# CY8C5868AXI_LP035 register map
File version: 0.1
Registers are 8-bit, read-write, no defined reset value unless marked. A register's access mark holds for its fields unless they carry their own. Offsets are from the block's base; [hi:lo] are bit positions.

## I2C_1
Base 0x00000000
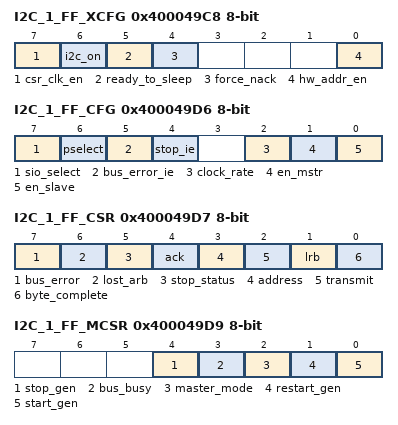
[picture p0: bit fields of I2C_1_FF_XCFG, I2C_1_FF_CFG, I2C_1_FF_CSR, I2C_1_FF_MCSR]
0x400049C8 I2C_1_FF_XCFG — Extended Configuration Register: I2C_XCFG
  [7] csr_clk_en, [6] i2c_on, [5] ready_to_sleep ro, [4] force_nack, [0] hw_addr_en
0x400049CA I2C_1_FF_ADDR — Slave Adddress Register: I2C_ADR
  [6:0] slave_address — This register holds the slave's 7-bit address.
0x400049D6 I2C_1_FF_CFG — Configuration Register: I2C_CFG
  [7] sio_select, [6] pselect, [5] bus_error_ie, [4] stop_ie, [2] clock_rate, [1] en_mstr, [0] en_slave
0x400049D7 I2C_1_FF_CSR — Control and Status Register: I2C_CSR
  [7] bus_error, [6] lost_arb, [5] stop_status, [4] ack, [3] address, [2] transmit, [1] lrb, [0] byte_complete
0x400049D8 I2C_1_FF_DATA — Data Register: I2C_D
  [7:0] data — This register provides read/write access to the Shift register.
0x400049D9 I2C_1_FF_MCSR — Master Control and Status Register: I2C_MCSR
  [4] stop_gen, [3] bus_busy ro, [2] master_mode ro, [1] restart_gen, [0] start_gen
0x400049DB I2C_1_FF__CLK_DIV1 — Divider of BUS_CLK low part: I2C_CLK_DIV1
  [7:0] Div
0x400049DC I2C_1_FF__CLK_DIV2 — Divider high part: I2C_CLK_DIV1
  [1:0] Div
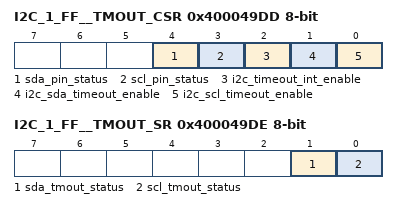
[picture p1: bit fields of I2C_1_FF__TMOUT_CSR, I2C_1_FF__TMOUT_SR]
0x400049DD I2C_1_FF__TMOUT_CSR — Extended Configuration Register: I2C_TMOUT_CSR
  [4] sda_pin_status, [3] scl_pin_status, [2] i2c_timeout_int_enable ro, [1] i2c_sda_timeout_enable, [0] i2c_scl_timeout_enable
0x400049DE I2C_1_FF__TMOUT_SR — Extended Configuration Register: I2C_TMOUT_SR
  [1] sda_tmout_status, [0] scl_tmout_status
0x400049DF I2C_1_FF__TMOUT_CFG0 — Extended Configuration Register: TMOUT_CFG0
  [7:0] timeout_period_lowbyte
0x400049E0 I2C_1_FF__TMOUT_CFG1 — Extended Configuration Register: TMOUT_CFG1
  [3:0] timeout_period_highnibble

## PC — UART
Base 0x00000000
0x4000642F RX_PC_RX_ADDRESS1 — RX Address1 Register
0x4000643F RX_PC_RX_ADDRESS2 — RX Address2 Register
0x4000644F RX_PC_RX_DATA — RX Data Register
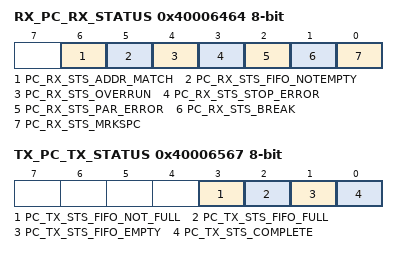
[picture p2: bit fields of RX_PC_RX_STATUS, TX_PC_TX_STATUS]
0x40006464 RX_PC_RX_STATUS — RX status register
  [6] PC_RX_STS_ADDR_MATCH ro, [5] PC_RX_STS_FIFO_NOTEMPTY ro, [4] PC_RX_STS_OVERRUN ro, [3] PC_RX_STS_STOP_ERROR ro, [2] PC_RX_STS_PAR_ERROR ro, [1] PC_RX_STS_BREAK ro, [0] PC_RX_STS_MRKSPC ro
0x40006547 TX_PC_TX_DATA — TX Data Register
0x40006567 TX_PC_TX_STATUS — TX status register
  [3] PC_TX_STS_FIFO_NOT_FULL ro, [2] PC_TX_STS_FIFO_FULL ro, [1] PC_TX_STS_FIFO_EMPTY ro, [0] PC_TX_STS_COMPLETE ro

## Surtidor — UART
Base 0x00000000
0x4000642E RX_Surtidor_RX_ADDRESS1 — RX Address1 Register
0x4000643E RX_Surtidor_RX_ADDRESS2 — RX Address2 Register
0x40006446 TX_Surtidor_TX_DATA — TX Data Register
0x4000644E RX_Surtidor_RX_DATA — RX Data Register
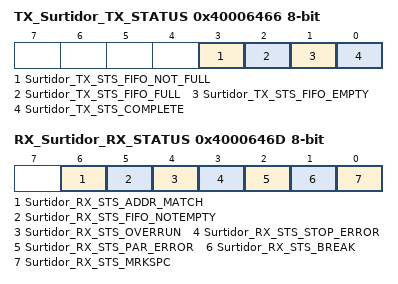
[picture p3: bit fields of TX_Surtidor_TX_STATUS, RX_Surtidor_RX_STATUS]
0x40006466 TX_Surtidor_TX_STATUS — TX status register
  [3] Surtidor_TX_STS_FIFO_NOT_FULL ro, [2] Surtidor_TX_STS_FIFO_FULL ro, [1] Surtidor_TX_STS_FIFO_EMPTY ro, [0] Surtidor_TX_STS_COMPLETE ro
0x4000646D RX_Surtidor_RX_STATUS — RX status register
  [6] Surtidor_RX_STS_ADDR_MATCH ro, [5] Surtidor_RX_STS_FIFO_NOTEMPTY ro, [4] Surtidor_RX_STS_OVERRUN ro, [3] Surtidor_RX_STS_STOP_ERROR ro, [2] Surtidor_RX_STS_PAR_ERROR ro, [1] Surtidor_RX_STS_BREAK ro, [0] Surtidor_RX_STS_MRKSPC ro

## Impresora — UART
Base 0x00000000
0x40006429 RX_Impresora_RX_ADDRESS1 — RX Address1 Register
0x40006439 RX_Impresora_RX_ADDRESS2 — RX Address2 Register
0x40006449 RX_Impresora_RX_DATA — RX Data Register
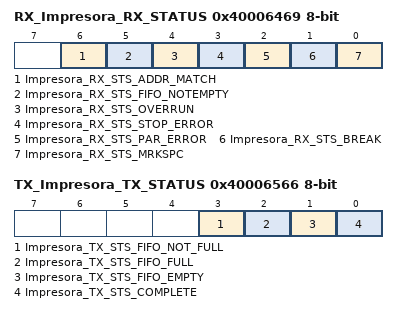
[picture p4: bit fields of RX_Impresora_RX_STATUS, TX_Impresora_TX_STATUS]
0x40006469 RX_Impresora_RX_STATUS — RX status register
  [6] Impresora_RX_STS_ADDR_MATCH ro, [5] Impresora_RX_STS_FIFO_NOTEMPTY ro, [4] Impresora_RX_STS_OVERRUN ro, [3] Impresora_RX_STS_STOP_ERROR ro, [2] Impresora_RX_STS_PAR_ERROR ro, [1] Impresora_RX_STS_BREAK ro, [0] Impresora_RX_STS_MRKSPC ro
0x40006546 TX_Impresora_TX_DATA — TX Data Register
0x40006566 TX_Impresora_TX_STATUS — TX status register
  [3] Impresora_TX_STS_FIFO_NOT_FULL ro, [2] Impresora_TX_STS_FIFO_FULL ro, [1] Impresora_TX_STS_FIFO_EMPTY ro, [0] Impresora_TX_STS_COMPLETE ro
